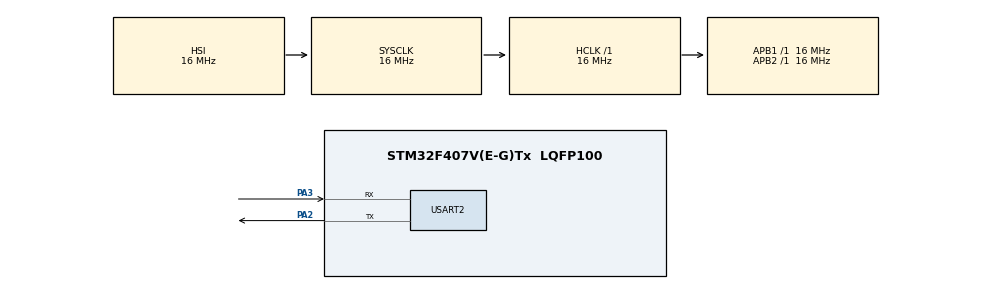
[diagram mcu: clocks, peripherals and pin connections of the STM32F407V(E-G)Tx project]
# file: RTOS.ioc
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Mcu.Family=STM32F4
Mcu.Name=STM32F407V(E-G)Tx
Mcu.Package=LQFP100
NVIC.PriorityGroup=NVIC_PRIORITYGROUP_4
PA2.Mode=Asynchronous
PA2.Signal=USART2_TX
PA3.Mode=Asynchronous
PA3.Signal=USART2_RX
ProjectManager.HeapSize=0x200
ProjectManager.StackSize=0x400
ProjectManager.TargetToolchain=Makefile
RCC.AHBFreq_Value=16000000
RCC.APB1Freq_Value=16000000
RCC.APB2Freq_Value=16000000
RCC.CortexFreq_Value=16000000
RCC.HSE_VALUE=25000000
RCC.HSI_VALUE=16000000
RCC.LSE_VALUE=32768
RCC.SYSCLKFreq_VALUE=16000000
RCC.VCOOutputFreq_Value=192000000
USART2.VirtualMode=VM_ASYNC
board=custom

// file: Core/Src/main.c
/* USER CODE BEGIN Header */
/**
  ******************************************************************************
  * @file           : main.c
  * @brief          : Main program body
  ******************************************************************************
  * @attention
  *
  * Copyright (c) 2025 STMicroelectronics.
  * All rights reserved.
  *
  * This software is licensed under terms that can be found in the LICENSE file
  * in the root directory of this software component.
  * If no LICENSE file comes with this software, it is provided AS-IS.
  *
  ******************************************************************************
  */
/* USER CODE END Header */
#include "main.h"

/* USER CODE BEGIN Includes */
#include <stdio.h>

#include "SEGGER_RTT.h"
#include "scheduler.h"
#include "task.h"
/* USER CODE END Includes */

/* USER CODE BEGIN PD */
#define TASK_STACK_SIZE 128
/* USER CODE END PD */

UART_HandleTypeDef huart2;

/* USER CODE BEGIN PV */
// === 정적 메모리 할당 (Static Allocation) ===
// 컴파일 타임에 메모리가 확보되므로 런타임 메모리 부족이나 단편화가 발생하지 않습니다.

// Task 1 (High Priority)
static TCB_t tcb_task1;
static uint32_t stack_task1[TASK_STACK_SIZE];

// Task 2 (Round Robin A)
static TCB_t tcb_task2;
static uint32_t stack_task2[TASK_STACK_SIZE];

// Task 3 (Round Robin B)
static TCB_t tcb_task3;
static uint32_t stack_task3[TASK_STACK_SIZE];
/* USER CODE END PV */

void SystemClock_Config(void);
static void MX_GPIO_Init(void);
static void MX_USART2_UART_Init(void);

/* USER CODE BEGIN 0 */
int __io_putchar(int ch)
{
  HAL_UART_Transmit(&huart2, (uint8_t *)&ch, 1, HAL_MAX_DELAY);
  return ch;
}

int _write(int file, char *ptr, int len)
{
  for (int i = 0; i < len; i++)
  {
    __io_putchar(*ptr++);
  }
  return len;
}

void Task1_Func(void *params)
{
    while (1)
    {
        printf("[Task 1] High Prio - Woke up!\r\n");
        // 100 틱 동안 Block (SysTick 핸들러가 카운트 증가시켜 깨워야 함)
        Task_Delay(100);
    }
}

void Task2_Func(void *params)
{
    volatile int i;
    while (1)
    {
        printf("  [Task 2] Round Robin A\r\n");
        // CPU 시간을 소비하여 타임 슬라이스 만료를 유도 (약간의 딜레이 루프)
        for(i=0; i<500000; i++);
    }
}

void Task3_Func(void *params)
{
    volatile int i;
    while (1)
    {
        printf("  [Task 3] Round Robin B\r\n");
        // CPU 시간을 소비하여 타임 슬라이스 만료를 유도
        for(i=0; i<500000; i++);
    }
}
/* USER CODE END 0 */

int main(void)
{

  /* USER CODE BEGIN 1 */
	//JLinkRTTViewer

  /* USER CODE END 1 */

  /* MCU Configuration--------------------------------------------------------*/

  /* Reset of all peripherals, Initializes the Flash interface and the Systick. */
  HAL_Init();

  /* Configure the system clock */
  SystemClock_Config();

  /* Initialize all configured peripherals */
  MX_GPIO_Init();
  MX_USART2_UART_Init();
  /* USER CODE BEGIN 2 */

  printf("Starting RTOS Test...\r\n");

    // 1. 태스크 생성
    // Stack Size: 128 words (512 bytes), TimeSlice: 10 ticks

  // Task 1: 우선순위 0 (최상위)
    // Task_CreateStatic(&TCB, 스택배열, 스택사이즈(Byte), 함수, 이름, 파라미터, 우선순위, 타임슬라이스)
  	Task_CreateStatic(&tcb_task1, stack_task1, sizeof(stack_task1),
                      Task1_Func, "Task1", NULL, 0, 10);

    // Task 2: 우선순위 1
    Task_CreateStatic(&tcb_task2, stack_task2, sizeof(stack_task2),
                      Task2_Func, "Task2", NULL, 1, 10);

    // Task 3: 우선순위 1
    Task_CreateStatic(&tcb_task3, stack_task3, sizeof(stack_task3),
                      Task3_Func, "Task3", NULL, 1, 10);

    printf("Starting Scheduler...\n");

    // 2. 스케줄러 시작 (여기서 제어권이 OS로 넘어가며, 리턴되지 않음)
    Task_StartScheduler();
  /* USER CODE END 2 */

  /* Infinite loop */
  while (1)
  {

    /* USER CODE BEGIN 3 */
	  printf("Hello RTT!\r\n");
	  HAL_Delay(1000);
  }
  /* USER CODE END 3 */
}

void SystemClock_Config(void)
{
  RCC_OscInitTypeDef RCC_OscInitStruct = {0};
  RCC_ClkInitTypeDef RCC_ClkInitStruct = {0};

  /** Configure the main internal regulator output voltage
  */
  __HAL_RCC_PWR_CLK_ENABLE();
  __HAL_PWR_VOLTAGESCALING_CONFIG(PWR_REGULATOR_VOLTAGE_SCALE1);

  /** Initializes the RCC Oscillators according to the specified parameters
  * in the RCC_OscInitTypeDef structure.
  */
  RCC_OscInitStruct.OscillatorType = RCC_OSCILLATORTYPE_HSI;
  RCC_OscInitStruct.HSIState = RCC_HSI_ON;
  RCC_OscInitStruct.HSICalibrationValue = RCC_HSICALIBRATION_DEFAULT;
  RCC_OscInitStruct.PLL.PLLState = RCC_PLL_NONE;
  if (HAL_RCC_OscConfig(&RCC_OscInitStruct) != HAL_OK)
  {
    Error_Handler();
  }

  /** Initializes the CPU, AHB and APB buses clocks
  */
  RCC_ClkInitStruct.ClockType = RCC_CLOCKTYPE_HCLK|RCC_CLOCKTYPE_SYSCLK
                              |RCC_CLOCKTYPE_PCLK1|RCC_CLOCKTYPE_PCLK2;
  RCC_ClkInitStruct.SYSCLKSource = RCC_SYSCLKSOURCE_HSI;
  RCC_ClkInitStruct.AHBCLKDivider = RCC_SYSCLK_DIV1;
  RCC_ClkInitStruct.APB1CLKDivider = RCC_HCLK_DIV1;
  RCC_ClkInitStruct.APB2CLKDivider = RCC_HCLK_DIV1;

  if (HAL_RCC_ClockConfig(&RCC_ClkInitStruct, FLASH_LATENCY_0) != HAL_OK)
  {
    Error_Handler();
  }
}

static void MX_USART2_UART_Init(void)
{

  huart2.Instance = USART2;
  huart2.Init.BaudRate = 115200;
  huart2.Init.WordLength = UART_WORDLENGTH_8B;
  huart2.Init.StopBits = UART_STOPBITS_1;
  huart2.Init.Parity = UART_PARITY_NONE;
  huart2.Init.Mode = UART_MODE_TX_RX;
  huart2.Init.HwFlowCtl = UART_HWCONTROL_NONE;
  huart2.Init.OverSampling = UART_OVERSAMPLING_16;
  if (HAL_UART_Init(&huart2) != HAL_OK)
  {
    Error_Handler();
  }

}

static void MX_GPIO_Init(void)
{

  /* GPIO Ports Clock Enable */
  __HAL_RCC_GPIOA_CLK_ENABLE();

}

void Error_Handler(void)
{
  __disable_irq();
  while (1)
  {
  }
}
